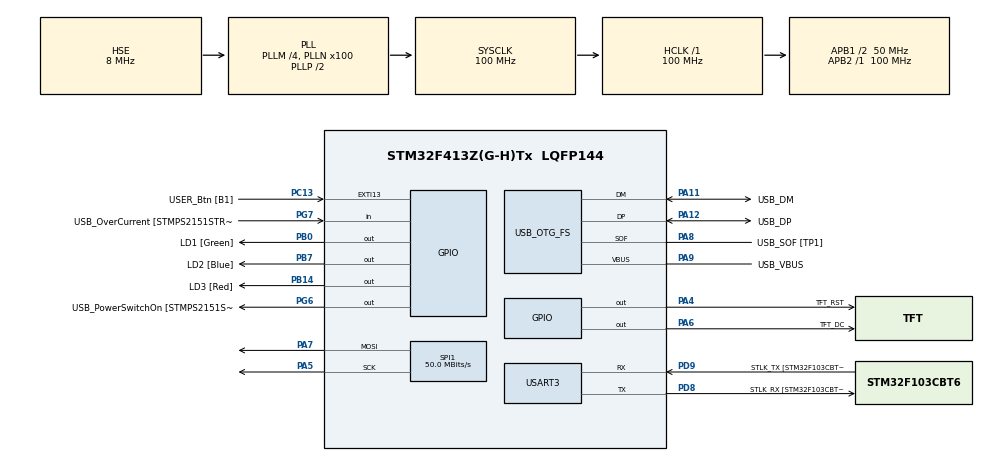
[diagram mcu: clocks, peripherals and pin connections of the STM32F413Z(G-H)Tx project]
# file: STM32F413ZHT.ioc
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Dma.Request0=SPI1_TX
Dma.SPI1_TX.0.Direction=DMA_MEMORY_TO_PERIPH
Dma.SPI1_TX.0.FIFOMode=DMA_FIFOMODE_DISABLE
Dma.SPI1_TX.0.Instance=DMA2_Stream2
Dma.SPI1_TX.0.MemDataAlignment=DMA_MDATAALIGN_BYTE
Dma.SPI1_TX.0.MemInc=DMA_MINC_ENABLE
Dma.SPI1_TX.0.Mode=DMA_NORMAL
Dma.SPI1_TX.0.PeriphDataAlignment=DMA_PDATAALIGN_BYTE
Dma.SPI1_TX.0.PeriphInc=DMA_PINC_DISABLE
Dma.SPI1_TX.0.Priority=DMA_PRIORITY_HIGH
Mcu.Family=STM32F4
Mcu.Name=STM32F413Z(G-H)Tx
Mcu.Package=LQFP144
NVIC.DMA2_Stream2_IRQn=true\:0\:0\:false\:false\:true\:false\:true\:true
NVIC.PriorityGroup=NVIC_PRIORITYGROUP_4
PA10.GPIO_Label=USB_ID
PA10.Signal=USB_OTG_FS_ID
PA11.GPIO_Label=USB_DM
PA11.Mode=Device_Only
PA11.Signal=USB_OTG_FS_DM
PA12.GPIO_Label=USB_DP
PA12.Mode=Device_Only
PA12.Signal=USB_OTG_FS_DP
PA13.GPIO_Label=TMS
PA13.Mode=Serial_Wire
PA13.Signal=SYS_JTMS-SWDIO
PA14.GPIO_Label=TCK
PA14.Mode=Serial_Wire
PA14.Signal=SYS_JTCK-SWCLK
PA4.GPIO_Label=TFT_RST
PA4.Signal=GPIO_Output
PA5.Mode=TX_Only_Simplex_Unidirect_Master
PA5.Signal=SPI1_SCK
PA6.GPIO_Label=TFT_DC
PA6.Signal=GPIO_Output
PA7.Mode=TX_Only_Simplex_Unidirect_Master
PA7.Signal=SPI1_MOSI
PA8.GPIO_Label=USB_SOF [TP1]
PA8.Mode=Activate_SOF_FS
PA8.Signal=USB_OTG_FS_SOF
PA9.GPIO_Label=USB_VBUS
PA9.Mode=Activate_VBUS
PA9.Signal=USB_OTG_FS_VBUS
PB0.GPIO_Label=LD1 [Green]
PB0.Signal=GPIO_Output
PB14.GPIO_Label=LD3 [Red]
PB14.Signal=GPIO_Output
PB3.GPIO_Label=SWO
PB3.Signal=SYS_JTDO-SWO
PB7.GPIO_Label=LD2 [Blue]
PB7.Signal=GPIO_Output
PC13.GPIO_Label=USER_Btn [B1]
PC13.Signal=GPXTI13
PC14-OSC32_IN.Mode=LSE-External-Oscillator
PC14-OSC32_IN.Signal=RCC_OSC32_IN
PC15-OSC32_OUT.Mode=LSE-External-Oscillator
PC15-OSC32_OUT.Signal=RCC_OSC32_OUT
PD8.GPIO_Label=STLK_RX [STM32F103CBT6_PA3]
PD8.Mode=Asynchronous
PD8.Signal=USART3_TX
PD9.GPIO_Label=STLK_TX [STM32F103CBT6_PA2]
PD9.Mode=Asynchronous
PD9.Signal=USART3_RX
PG6.GPIO_Label=USB_PowerSwitchOn [STMPS2151STR_EN]
PG6.Signal=GPIO_Output
PG7.GPIO_Label=USB_OverCurrent [STMPS2151STR_FAULT]
PG7.Signal=GPIO_Input
PH0\ -\ OSC_IN.GPIO_Label=MCO
PH0\ -\ OSC_IN.Mode=HSE-External-Clock-Source
PH0\ -\ OSC_IN.Signal=RCC_OSC_IN
PH1\ -\ OSC_OUT.Mode=HSE-External-Clock-Source
PH1\ -\ OSC_OUT.Signal=RCC_OSC_OUT
ProjectManager.HeapSize=0x200
ProjectManager.StackSize=0x800
ProjectManager.TargetToolchain=STM32CubeIDE
RCC.48MHZClocksFreq_Value=24000000
RCC.AHBFreq_Value=100000000
RCC.APB1CLKDivider=RCC_HCLK_DIV2
RCC.APB1Freq_Value=50000000
RCC.APB1TimFreq_Value=100000000
RCC.APB2Freq_Value=100000000
RCC.APB2TimFreq_Value=100000000
RCC.CortexFreq_Value=100000000
RCC.HCLKFreq_Value=100000000
RCC.HSE_VALUE=8000000
RCC.HSI_VALUE=16000000
RCC.PLLI2SM=4
RCC.PLLI2SN=72
RCC.PLLI2SQ=3
RCC.PLLM=4
RCC.PLLMUL=RCC_PLL_MUL9
RCC.PLLN=100
RCC.PLLQ=8
RCC.PRESCALERUSB=RCC_USBCLKSOURCE_PLL_DIV1_5
RCC.SYSCLKFreq_VALUE=100000000
RCC.SYSCLKSource=RCC_SYSCLKSOURCE_PLLCLK
RCC.SYSCLKSourceVirtual=RCC_SYSCLKSOURCE_PLLCLK
RCC.USBCLockSelection=RCC_CLK48CLKSOURCE_PLLI2SQ
RCC.USBFreq_Value=48000000
RCC.VCOOutputFreq_Value=200000000
SPI1.CLKPhase=SPI_PHASE_2EDGE
SPI1.CLKPolarity=SPI_POLARITY_HIGH
SPI1.CalculateBaudRate=50.0 MBits/s
SPI1.Direction=SPI_DIRECTION_2LINES
SPI1.Mode=SPI_MODE_MASTER
SPI1.VirtualType=VM_MASTER
USART3.VirtualMode=VM_ASYNC
USB_OTG_FS.VirtualMode=Device_Only
board=NUCLEO-F413ZH

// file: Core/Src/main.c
/* USER CODE BEGIN Header */
/**
  ******************************************************************************
  * @file           : main.c
  * @brief          : Main program body
  ******************************************************************************
  * @attention
  *
  * Copyright (c) 2022 STMicroelectronics.
  * All rights reserved.
  *
  * This software is licensed under terms that can be found in the LICENSE file
  * in the root directory of this software component.
  * If no LICENSE file comes with this software, it is provided AS-IS.
  *
  ******************************************************************************
  */
/* USER CODE END Header */
#include "main.h"
#include "dma.h"
#include "spi.h"
#include "usart.h"
#include "usb_otg.h"
#include "gpio.h"
#include "DataType.h"
#include <string.h>
//#include "LVGL_UI.h"

void SystemClock_Config(void);

/* USER CODE BEGIN 0 */

u16 data[240*20];
u8 Flag = 1;
/* USER CODE END 0 */

int main(void)
{

  /* MCU Configuration--------------------------------------------------------*/

  /* Reset of all peripherals, Initializes the Flash interface and the Systick. */
  HAL_Init();

  /* Configure the system clock */
  SystemClock_Config();

  /* Initialize all configured peripherals */
  MX_GPIO_Init();
  MX_DMA_Init();
  MX_USART3_UART_Init();
  MX_USB_OTG_FS_PCD_Init();
  MX_SPI1_Init();
  /* USER CODE BEGIN 2 */
  ST7789_Init();
  /* USER CODE END 2 */

  /* Infinite loop */
  while (1)
  {

    /* USER CODE BEGIN 3 */
	  if( TFT_DMA_GetTXComplateFlag() == TRUE)
	  {
		  if(Flag == 1)
		  {
			  memset(data,0x00,sizeof(data));
			  Flag = 2;
		  }
		  else
		  {
			  memset(data,0xff,sizeof(data));
			  Flag = 1;
		  }

		  ST7789_SetArea(0,0,239,19);
		  TFT_DMA_SetAddr((u32)data,sizeof(data)/2);
		  TFT_DMA_Start();
	  }
  }
  /* USER CODE END 3 */
}

void SystemClock_Config(void)
{
  RCC_OscInitTypeDef RCC_OscInitStruct = {0};
  RCC_ClkInitTypeDef RCC_ClkInitStruct = {0};

  /** Configure the main internal regulator output voltage
  */
  __HAL_RCC_PWR_CLK_ENABLE();
  __HAL_PWR_VOLTAGESCALING_CONFIG(PWR_REGULATOR_VOLTAGE_SCALE1);

  /** Initializes the RCC Oscillators according to the specified parameters
  * in the RCC_OscInitTypeDef structure.
  */
  RCC_OscInitStruct.OscillatorType = RCC_OSCILLATORTYPE_HSE;
  RCC_OscInitStruct.HSEState = RCC_HSE_BYPASS;
  RCC_OscInitStruct.PLL.PLLState = RCC_PLL_ON;
  RCC_OscInitStruct.PLL.PLLSource = RCC_PLLSOURCE_HSE;
  RCC_OscInitStruct.PLL.PLLM = 4;
  RCC_OscInitStruct.PLL.PLLN = 100;
  RCC_OscInitStruct.PLL.PLLP = RCC_PLLP_DIV2;
  RCC_OscInitStruct.PLL.PLLQ = 8;
  RCC_OscInitStruct.PLL.PLLR = 2;
  if (HAL_RCC_OscConfig(&RCC_OscInitStruct) != HAL_OK)
  {
    Error_Handler();
  }

  /** Initializes the CPU, AHB and APB buses clocks
  */
  RCC_ClkInitStruct.ClockType = RCC_CLOCKTYPE_HCLK|RCC_CLOCKTYPE_SYSCLK
                              |RCC_CLOCKTYPE_PCLK1|RCC_CLOCKTYPE_PCLK2;
  RCC_ClkInitStruct.SYSCLKSource = RCC_SYSCLKSOURCE_PLLCLK;
  RCC_ClkInitStruct.AHBCLKDivider = RCC_SYSCLK_DIV1;
  RCC_ClkInitStruct.APB1CLKDivider = RCC_HCLK_DIV2;
  RCC_ClkInitStruct.APB2CLKDivider = RCC_HCLK_DIV1;

  if (HAL_RCC_ClockConfig(&RCC_ClkInitStruct, FLASH_LATENCY_3) != HAL_OK)
  {
    Error_Handler();
  }
}

void Error_Handler(void)
{
  __disable_irq();
  while (1)
  {
  }
}
